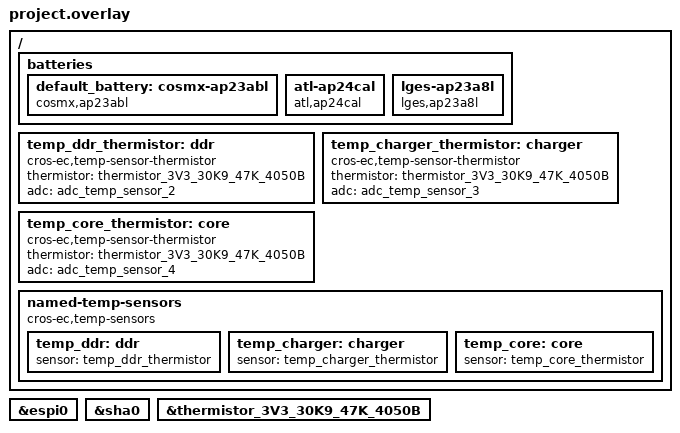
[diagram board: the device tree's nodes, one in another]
/* Copyright 2025 The ChromiumOS Authors
 * Use of this source code is governed by a BSD-style license that can be
 * found in the LICENSE file.
 */

/* kinmen program common DTS includes */

#include <cros/integrated_fwid.dtsi>
#include <cros/thermistor/thermistor.dtsi>

/* kinmen project DTS includes */
#include "adc.dtsi"
#include "binman.dtsi"
#include "console.dtsi"
#include "fan.dtsi"
#include "gpios.dtsi"
#include "hibernate.dtsi"
#include "i2c.dtsi"
#include "interrupts.dtsi"
#include "keyboard.dtsi"
#include "led_pins.dtsi"
#include "led_policy.dtsi"
#include "power_signals.dtsi"
#include "pwm.dtsi"
#include "usb_typec.dtsi"
#include "usba.dtsi"

/ {
	batteries {
		default_battery: cosmx-ap23abl {
			compatible = "cosmx,ap23abl", "battery-smart";
		};
		atl-ap24cal {
			compatible = "atl,ap24cal", "battery-smart";
		};
		lges-ap23a8l {
			compatible = "lges,ap23a8l", "battery-smart";
		};
	};

	temp_ddr_thermistor: ddr {
		compatible = "cros-ec,temp-sensor-thermistor";
		thermistor = <&thermistor_3V3_30K9_47K_4050B>;
		adc = <&adc_temp_sensor_2>;
	};
	temp_charger_thermistor: charger {
		compatible = "cros-ec,temp-sensor-thermistor";
		thermistor = <&thermistor_3V3_30K9_47K_4050B>;
		adc = <&adc_temp_sensor_3>;
	};
	temp_core_thermistor: core {
		compatible = "cros-ec,temp-sensor-thermistor";
		thermistor = <&thermistor_3V3_30K9_47K_4050B>;
		adc = <&adc_temp_sensor_4>;
	};

	named-temp-sensors {
		compatible = "cros-ec,temp-sensors";
		temp_ddr: ddr {
			sensor = <&temp_ddr_thermistor>;
		};
		temp_charger: charger {
			sensor = <&temp_charger_thermistor>;
		};
		temp_core: core {
			sensor = <&temp_core_thermistor>;
		};
	};
};

/* AP interface */
&espi0 {
	status = "okay";
};

&sha0 {
	status = "okay";
};

&thermistor_3V3_30K9_47K_4050B {
	status = "okay";
};
